# nrf7140_application register map
Vendor: Nordic Semiconductor; Series: nRF71; File version: 1
CPU: CM33 r0p4, little endian, MPU, FPU, 3 interrupt priority bits, 480 interrupts, 8 SAU regions
Registers are 32-bit, read-write, reset 0x0 unless marked. A register's access mark holds for its fields unless they carry their own. Offsets are from the block's base; [hi:lo] are bit positions; lines under a group give offsets from that group; {n}, {i} and the like mark numbered series; 'fields as' and 'values as' point back to an identical list.

## GLOBAL_DISPC_NS (part 2 of 3) — DISPC
Base 0x49004000
0x1000 CORE group — Unspecified
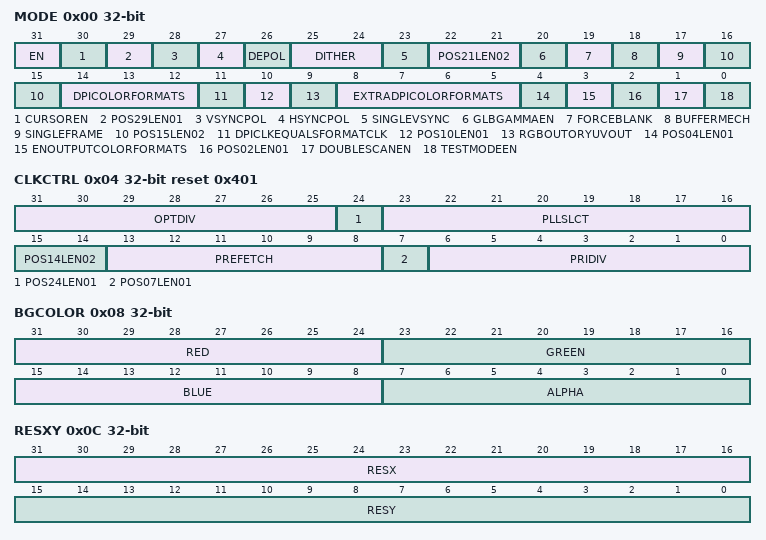
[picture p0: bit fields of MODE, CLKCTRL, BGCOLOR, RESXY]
  0x00 MODE — General control register that activates the NemaDC
    [31] EN — When set to 1, the NemaDC controller is activated
    [30] CURSOREN — When set to 1, cursor is enabled
    [29] POS29LEN01
    [28] VSYNCPOL — Defines VSYNC polarity
    [27] HSYNCPOL — Defines HSYNC polarity
    [26] DEPOL — Defines DE polarity
    [25:24] DITHER — Defines the dithering mode
    [23] SINGLEVSYNC — When set to 1, VSYNC for a single cycle per line is enabled
    [22:21] POS21LEN02
    [20] GLBGAMMAEN — When set to 1, global gamma correction is enabled
    [19] FORCEBLANK — When set to 1, forces output to blank
    [18] BUFFERMECH — When set to 1, a buffer mechanism is enable that waits for the internal
    [17] SINGLEFRAME — When set to 1, single frame update is enabled
    [16:15] POS15LEN02
    [14:12] DPICOLORFORMATS — DPI output color formats
    [11] DPICLKEQUALSFORMATCLK — When set to 1, DPI_PCLK is equal to format_clk
    [10] POS10LEN01
    [9] RGBOUTORYUVOUT — * 1: YUV/YCbCr format is enabled
    [8:5] EXTRADPICOLORFORMATS — Display data format
    [4] POS04LEN01
    [3] ENOUTPUTCOLORFORMATS — When set to 0, the following output color formats are enabled
    [2] POS02LEN01
    [1] DOUBLESCANEN — When set to 1, double horizontal scan is enabled
    [0] TESTMODEEN — When set to 1, test mode is enabled
  0x04 CLKCTRL reset 0x401 — Setup proper timing with divider control bits
    [31:25] OPTDIV — Value of predivider
    [24] POS24LEN01
    [23:16] PLLSLCT — Select PLL Clock. Drives the pll_sw pins
    [15:14] POS14LEN02
    [13:8] PREFETCH — Number of lines to be prefetched before starting the
    [7] POS07LEN01
    [6:0] PRIDIV — Value of primary clock divider
  0x08 BGCOLOR — Specifies the main background color.
    [31:24] RED — Color red is used as background color
    [23:16] GREEN — Color green is used as background color
    [15:8] BLUE — Color blue is used as background color
    [7:0] ALPHA — Color alpha is used as background color
  0x0C RESXY — Specifies the main X and Y resolutions.
    [31:16] RESX — Value of X resolution in pixels
    [15:0] RESY — Value of Y resolution in pixels
  0x10 PLAY — Write any value to this register at the end of the programming sequence to trigger the NemaDC.
    [31:0] PLAY — Trigger the frame generation process
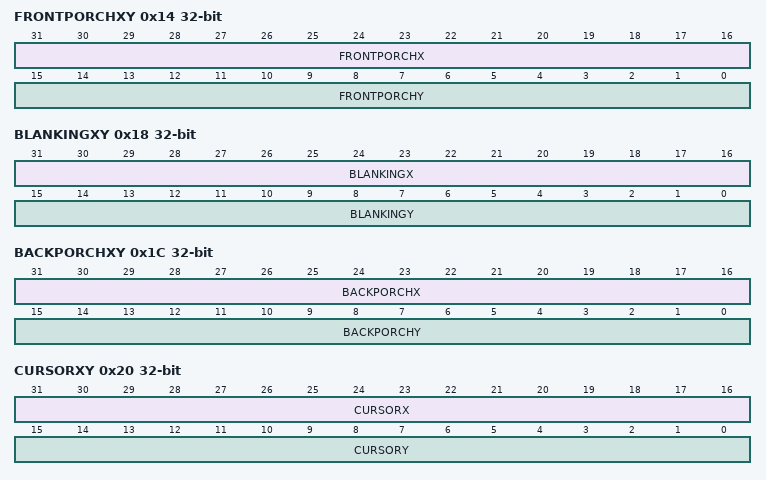
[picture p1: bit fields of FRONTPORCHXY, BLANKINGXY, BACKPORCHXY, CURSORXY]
  0x14 FRONTPORCHXY — Specifies the X and Y dimensions for the Front Porch.
    [31:16] FRONTPORCHX — Specify the pixel clock cycles for the front porch X dimension
    [15:0] FRONTPORCHY — Specify the number of lines for the front porch Y dimension
  0x18 BLANKINGXY — Specifies the X and Y dimensions for the Blanking Period.
    [31:16] BLANKINGX — Specify the HSYNC pulse length for the X dimension blanking period
    [15:0] BLANKINGY — Specify the VSYNC lines for the Y dimension blanking period
  0x1C BACKPORCHXY — Specifies the X and Y dimensions for the Back Porch.
    [31:16] BACKPORCHX — Specify the pixel clock cycles for the back porch X dimension
    [15:0] BACKPORCHY — Specify the number of lines for the front porch Y dimension
  0x20 CURSORXY — Specifies the cursor's start X and Y coordinates.
    [31:16] CURSORX — Specify cursor's X dimension
    [15:0] CURSORY — Specify cursor's Y dimension
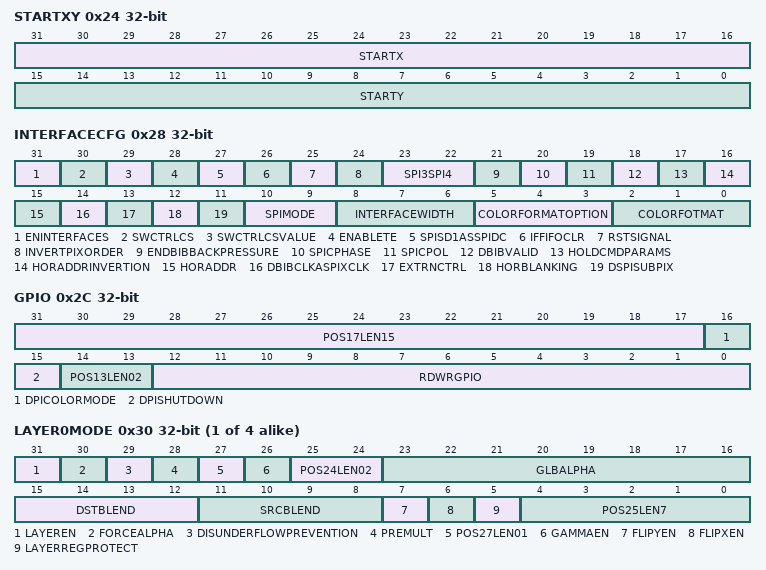
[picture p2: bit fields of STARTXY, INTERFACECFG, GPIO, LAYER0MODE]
  0x24 STARTXY — Specifies the start position of the very first frame.
    [31:16] STARTX — Specify frames's X dimension
    [15:0] STARTY — Specify frames's Y dimension
  0x28 INTERFACECFG — Register for the configuration DBI Type-B interface
    [31] ENINTERFACES — When set to 1, the DBI Type-B/SPI interfaces are activated
    [30] SWCTRLCS — When set to 1, the value of the CSX signal of the DBI Type-B/SPI interfaces
    [29] SWCTRLCSVALUE — Sets the value of DBIB_CSX or SPI_CS signal:
    [28] ENABLETE — When set to 1, the INTERFACE_TE signal is enabled
    [27] SPISD1ASSPIDC — When set to 1, enables the usage of SPI_DC wire as SPI_SD1
    [26] IFFIFOCLR — When set to 1, it clears the data FIFO and the command FIFO
    [25] RSTSIGNAL — Drives DBIB_RESX output signal of DBI Type-B interface
    [24] INVERTPIXORDER — Invert Pixel Order
    [23:22] SPI3SPI4 — Set the SPI 3-wire or 4-wire mode:
    [21] ENDBIBBACKPRESSURE — When set to 1, enables back-pressure for DBI Type-B
    [20] SPICPHASE — Sets SPI Clock Phase
    [19] SPICPOL — Sets SPI Clock Polarity
    [18] DBIBVALID — When set to 1 and a DBIB read operation is performed then it is necessary
    [17] HOLDCMDPARAMS — When set to 1, it holds the commands/parameters and transmit them
    [16] HORADDRINVERTION — When set to 1, inverts the bit-order of the horizontal line address
    [15] HORADDR — When set to 1, two-byte address is sent with each horizontal line (SPI)
    [14] DBIBCLKASPIXCLK — When set to 1, expose pixel generation pipeline clock (pixel_clk) on the DBIB_CLK
    [13] EXTRNCTRL — When set to 1, enables the external control.
    [12] HORBLANKING — When set to 1, enables the horizontal blanking
    [11] DSPISUBPIX — When set to 1, Enables DualSPI sub-pixel transaction
    [10:9] SPIMODE — Set mode of operation SPI/DualSPI/QuadSPI/QuadSPI DDR
    [8:6] INTERFACEWIDTH — Set DBI Type-B interface width (8, 9 or 16 bits) and
    [5:3] COLORFORMATOPTION — Set the data order of the 8-bit data word:
    [2:0] COLORFOTMAT — Set the color format for DBI Type-B/SPI interfaces:
  0x2C GPIO — General Purpose register.
    [31:17] POS17LEN15
    [16] DPICOLORMODE wo — Assert DPI-2 Color Mode Signal
    [15] DPISHUTDOWN wo — Assert DPI-2 Shutdown Signal
    [14:13] POS13LEN02
    [12:0] RDWRGPIO — Read/Write from/to GPIO pins
  {0x30+0x20*j} LAYER{j}MODE (j=0..3) — Activate and set-up layer {j}
    [31] LAYEREN — When set to 1, layer n is enabled
    [30] FORCEALPHA — When set to 1, force alpha with global alpha
    [29] DISUNDERFLOWPREVENTION — When set to 1, it disables the mechanism that prevent the underflow
    [28] PREMULT — When set to 1, premultiply image alpha is enabled
    [27] POS27LEN01
    [26] GAMMAEN — When set to 1, Gamma Look Up Table is enabled
    [25:24] POS24LEN02
    [23:16] GLBALPHA — Alpha layer global value (0x00-0xFF range)
    [15:12] DSTBLEND — Destination blending function for layer {j}.
    [11:8] SRCBLEND — Source blending function for layer {j}.
    [7] FLIPYEN — Enables the FlipY functionality
    [6] FLIPXEN — Enables the FlipX functionality.
    [5] LAYERREGPROTECT — Enable Register Protection for NemaDC layer registers.
    [4:0] POS25LEN7
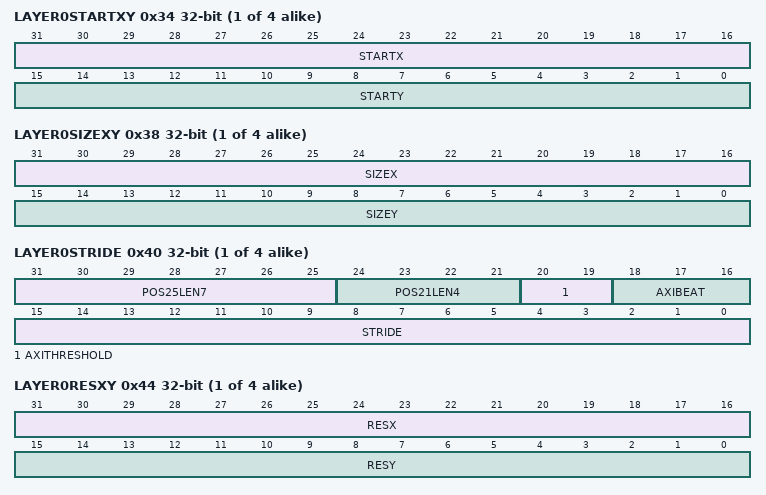
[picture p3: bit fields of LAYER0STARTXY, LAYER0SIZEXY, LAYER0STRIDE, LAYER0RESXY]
  {0x34+0x20*j} LAYER{j}STARTXY (j=0..3) — X and Y start dimensions of layer {j}
    [31:16] STARTX — Specify the pixel offset of the starting X dimension of layer {j}
    [15:0] STARTY — Specify the pixel offset of the starting Y dimension of layer {j}
  {0x38+0x20*j} LAYER{j}SIZEXY (j=0..3) — X and Y size of layer {j}
    [31:16] SIZEX — Specify the pixel size of the layer {j} in the X dimension
    [15:0] SIZEY — Specify the pixel size of the layer {j} in the Y dimension
  {0x3C+0x20*j} LAYER{j}BASEADDR (j=0..3) — The start address of the framebuffer to be accessed by layer {j}
    [31:0] BASEADDR — Specify the start address of framebuffer for layer {j}.
  {0x40+0x20*j} LAYER{j}STRIDE (j=0..3) — Specify the stride and the AXI bus burst of layer {j}
    [31:25] POS25LEN7
    [24:21] POS21LEN4
    [20:19] AXITHRESHOLD — Specify the AXI fifo threshold burst start in layer {j}
    [18:16] AXIBEAT — Specify the AXI-beats per burst in layer {j}
    [15:0] STRIDE — Specify the stride, which is the distance from line to line in bytes for layer {j} memory
  {0x44+0x20*j} LAYER{j}RESXY (j=0..3) — X and Y start dimensions of layerX and Y dimensions for the resolution of layer {j}.
    [31:16] RESX — Specify the layer {j} pixel resolution in the X dimension
    [15:0] RESY — Specify the layer {j} pixel resolution in the Y dimension
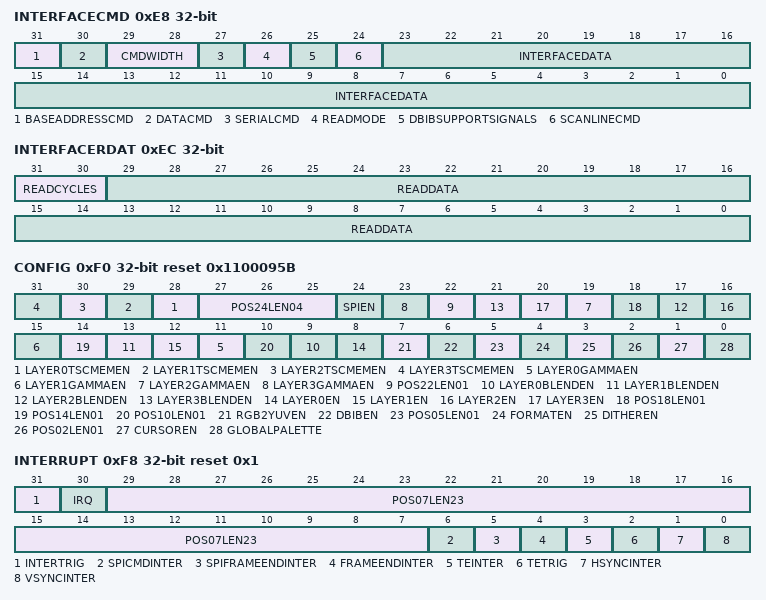
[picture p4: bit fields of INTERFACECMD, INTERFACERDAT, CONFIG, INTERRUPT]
  0xE8 INTERFACECMD — Command Register to read/write commands from/to DBI Type-B/SPI interfaces.
    [31] BASEADDRESSCMD — When set to 0, indicates that the command data are
    [30] DATACMD — Send direct data of type 'command' to the DBI Type-B/SPI interfaces
    [29:28] CMDWIDTH — Determine the command width.
    [27] SERIALCMD — When sets to 1, switch to serial transmission of the
    [26] READMODE — When sets to 1, read mode is enabled
    [25] DBIBSUPPORTSIGNALS — When sets to 1, NEMADC_REG_FORMAT_CTRL[15:8] is exposed on DBIB_CT pins and
    [24] SCANLINECMD — When sets to 1, store internally a command type which is
    [23:0] INTERFACEDATA — Data to send to the DBI Type-B/SPI interfaces
  0xEC INTERFACERDAT — Data read by DBI Type-B/SPI interfaces are stored in the NEMADC_REG_INTERFACE_RDAT register.
    [31:30] READCYCLES — On Write: Specify the number of read cycles for SPI
    [29:0] READDATA ro — Read data from DBI Type-B/SPI interfaces (low bits)
  0xF0 CONFIG reset 0x1100095B — Information register of the layers activation and setup.
    [n+28] LAYER{n}TSCMEMEN ro (n=0..3) — Indicates that layer {n} has TSC Memory
    [27:25] POS24LEN04 ro
    [24] SPIEN ro — Indicates that SPI interface is enabled
    [4n+11] LAYER{n}GAMMAEN ro (n=0..3) — Indicates that layer {n} has gamma LUT
    [22] POS22LEN01 ro
    [4n+9] LAYER{n}BLENDEN ro (n=0..3) — Indicates that layer {n} has blender
    [4n+8] LAYER{n}EN ro (n=0..3) — Indicates that layer {n} is enabled
    [18] POS18LEN01 ro
    [14] POS14LEN01 ro
    [10] POS10LEN01 ro
    [7] RGB2YUVEN ro — Indicates that RGB to YUV/YCbCr converter is enabled
    [6] DBIBEN ro — Indicates that DBI Type-B interface is enabled
    [5] POS05LEN01 ro
    [4] FORMATEN ro — Indicates that formatting is enabled
    [3] DITHEREN ro — Indicates that dithering is enabled
    [2] POS02LEN01 ro
    [1] CURSOREN ro — Indicates that cursor is enabled
    [0] GLOBALPALETTE ro — Indicates that Global Gamma/Palette is enabled
  0xF4 IDREG reset 0x87452365 — Identification Register.
    [31:0] IDREG ro — Constant ID value
  0xF8 INTERRUPT reset 0x1
    [31] INTERTRIG — Interrupt request trigger control
    [30] IRQ ro — Indicates IRQ is underway
    [29:7] POS07LEN23
    [6] SPICMDINTER — When set to 1, signals an interrupt when SPI interfaces
    [5] SPIFRAMEENDINTER — When set to 1, signals an interrupt when SPI interfaces
    [4] FRAMEENDINTER — When set to 1, signals an interrupt on Frame End
    [3] TEINTER — When set to 1, TE interrupt enabled
    [2] TETRIG — TE interrupt trigger control
    [1] HSYNCINTER — When set to 1, HSYNC interrupt enabled
    [0] VSYNCINTER — When set to 1, VSYNC interrupt enabled
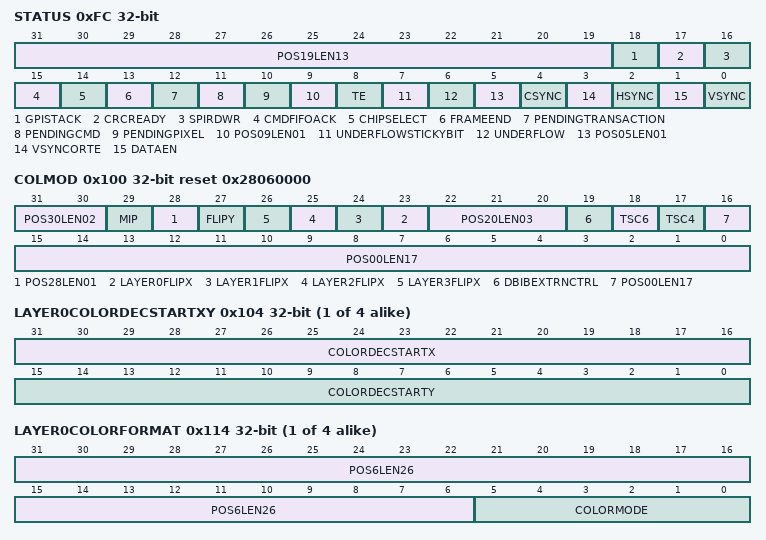
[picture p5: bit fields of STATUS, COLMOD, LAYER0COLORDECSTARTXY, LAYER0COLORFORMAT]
  0xFC STATUS — On read, returns NemaDC's status.
    [31:19] POS19LEN13 ro
    [18] GPISTACK ro — Indicates GPI got stack durring packet transaction
    [17] CRCREADY ro — Indicates CRC Register read ready
    [16] SPIRDWR ro — Indicates read/write operation on SPI
    [15] CMDFIFOACK ro — Indicates the DBI/SPI Command fifo ack
    [14] CHIPSELECT ro — Indicates DBI/SPI CS status
    [13] FRAMEEND ro — Indicates Frame end
    [12] PENDINGTRANSACTION ro — Indicates pending output transaction in DBI Type-B/SPI interfaces
    [11] PENDINGCMD ro — Indicates pending commands in DBI Type-B/SPI interfaces
    [10] PENDINGPIXEL ro — Indicates pending RGB data in DBI Type-B/SPI interfaces
    [9] POS09LEN01 ro
    [8] TE ro — Indicates DBI Type-B/SPI tearing effect
    [7] UNDERFLOWSTICKYBIT ro — Indicates sticky underflow. This bit clears when status register is written
    [6] UNDERFLOW ro — Indicates current underflow
    [5] POS05LEN01 ro
    [4] CSYNC ro — Indicates the CSYNC signal status (0 or 1) at the current time of reading
    [3] VSYNCORTE ro — Indicates the VSYNC signal status and the tearing effect signal
    [2] HSYNC ro — Indicates the HSYNC signal status (0 or 1) at the current time of reading
    [1] DATAEN ro — Indicates the DE signal status (0 or 1) at the current time of reading
    [0] VSYNC ro — Indicates that the controller is not in active vertical blanking
  0x100 COLMOD reset 0x28060000 — Color mode status register.
    [31:30] POS30LEN02 ro
    [29] MIP ro — High value indicate that NemaDC is equiped with MiP-Parallel interface
    [28] POS28LEN01 ro
    [27] FLIPY ro — High value indicate that FlipY is equiped
    [n+23] LAYER{n}FLIPX ro (n=0..3) — High value indicate that FlipX is equiped for Layer {n}
    [22:20] POS20LEN03 ro
    [19] DBIBEXTRNCTRL ro — High value indicate that DBIB external control is enabled
    [18] TSC6 ro — High value indicate that TSC6 is enabled
    [17] TSC4 ro — High value indicates that TSC4 is enabled
    [16:0] POS00LEN17 ro
  {0x104+4j} LAYER{j}COLORDECSTARTXY (j=0..3) — X and Y start dimensions of colordec in layer {j}
    [31:16] COLORDECSTARTX — Specify the pixel offset of the starting X dimension of colordec in layer {j}.
    [15:0] COLORDECSTARTY — Specify the pixel offset of the starting Y dimension of colordec in layer {j}.
  {0x114+4j} LAYER{j}COLORFORMAT (j=0..3) — Specify the color format of layer {j}
    [31:6] POS6LEN26
    [5:0] COLORMODE — Color mode for layer {j}.
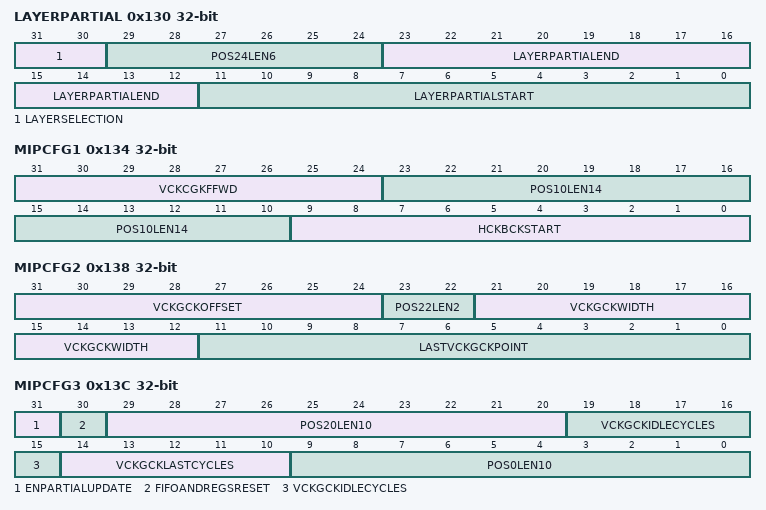
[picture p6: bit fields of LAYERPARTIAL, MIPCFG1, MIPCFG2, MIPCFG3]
  0x130 LAYERPARTIAL — MiP partial and full frame update register, used by layers.
    [31:30] LAYERSELECTION — Indicates the layer that the partial or full frame region belongs to.
    [29:24] POS24LEN6
    [23:12] LAYERPARTIALEND — Indicates the last visible row of the layer for the given partial or full frame region.
    [11:0] LAYERPARTIALSTART — Indicates the first visible row of the layer for the given partial or full frame region.
  0x134 MIPCFG1 — MiP partial and full frame update configuration register, used by MiP-Parallel interface.
    [31:24] VCKCGKFFWD — Indicates the VCK/GCK (high/low) width of a fast forward transaction
    [23:10] POS10LEN14
    [9:0] HCKBCKSTART — Indicates the HCK/BCK count that the MiP-Parallel interface
  0x138 MIPCFG2 — MiP partial and full frame update configuration register, used by MiP-Parallel interface.
    [31:24] VCKGCKOFFSET — Indicates the VCK/GCK offset.
    [23:22] POS22LEN2
    [21:12] VCKGCKWIDTH — Indicates the VCK/GCK (high/low) width during a normal transaction.
    [11:0] LASTVCKGCKPOINT — Indicates the last VCK/GCK count with valid data.
  0x13C MIPCFG3 — MiP partial and full frame update configuration register, used by MiP-Parallel interface.
    [31] ENPARTIALUPDATE — Enables partial update in MiP-Parallel interface.
    [30] FIFOANDREGSRESET — When set to 1, it resets all the MiP-Parallel interface fifos and registers. Layers must be active.
    [29:20] POS20LEN10
    [19:15] VCKGCKIDLECYCLES — Indicates the VCK/GCK idle counts before the transmission of valid data.
    [14:10] VCKGCKLASTCYCLES — Indicates the number of the last VCK/GCK counts that are transmitted
    [9:0] POS0LEN10
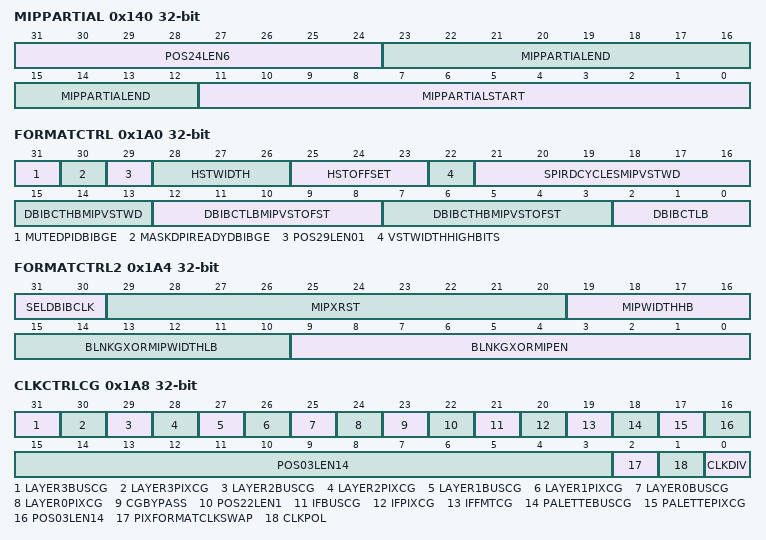
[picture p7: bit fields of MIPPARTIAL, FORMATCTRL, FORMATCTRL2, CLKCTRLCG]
  0x140 MIPPARTIAL — MiP partial and full frame update register, used by MiP-Parallel interface.
    [31:24] POS24LEN6
    [23:12] MIPPARTIALEND — Indicates the last row of the given partial or full frame region.
    [11:0] MIPPARTIALSTART — Indicates the first row of the given partial or full frame region.
  0x180 IPVERSION reset 0x230601 — Indicates the current version of NemaDC IP
    [31:0] TLCDVERSION ro — The current version of NemaDC IP
  0x184 CRC — If CRC errors occur, they are written in the NEMADC_REG_CRC register
    [31:0] CRC ro — CRC value if CRC error exists
  0x1A0 FORMATCTRL — Controls SPI, DBI and MiP-Parallel format.
    [31] MUTEDPIDBIBGE — When DBI-Type B Interface is selected
    [30] MASKDPIREADYDBIBGE — When DBI-Type B Interface is selected
    [29] POS29LEN01
    [28:26] HSTWIDTH — When DBI-Type B or SPI Interfaces is selected
    [25:23] HSTOFFSET — When DBI-Type B or SPI Interfaces is selected
    [22] VSTWIDTHHIGHBITS — When DBI-Type B or SPI Interfaces is selected
    [21:16] SPIRDCYCLESMIPVSTWD — When SPI Interface is selected
    [15:13] DBIBCTHBMIPVSTWD — When DBI-Type B Interface is selected
    [12:8] DBIBCTLBMIPVSTOFST — When DBI-Type B Interface is selected
    [7:3] DBIBCTHBMIPVSTOFST — When DBI-Type B Interface is selected
    [2:0] DBIBCTLB — When DBI-Type B Interface is selected
  0x1A4 FORMATCTRL2 — Controls DBI, SPI and MiP-Parallel format.
    [31:30] SELDBIBCLK — Set the exposition of DBIB_CLK based on the following options:
    [29:20] MIPXRST — When DBI-Type B or SPI Interface is selected
    [19:16] MIPWIDTHHB — When DBI-Type B or SPI Interface is selected
    [15:10] BLNKGXORMIPWIDTHLB — When DBI-Type B or SPI Interface is selected
    [9:0] BLNKGXORMIPEN — When DBI-Type B or SPI Interface is selected
  0x1A8 CLKCTRLCG — Controls the Clock Gaters and the routing of format and pixel clock
    [31] LAYER3BUSCG wo — layer 3 bus clock clock-gater bypass
    [30] LAYER3PIXCG wo — layer 3 pixel clock clock-gater bypass
    [29] LAYER2BUSCG wo — layer 2 bus clock clock-gater bypass
    [28] LAYER2PIXCG wo — layer 2 pixel clock clock-gater bypass
    [27] LAYER1BUSCG wo — layer 1 bus clock clock-gater bypass
    [26] LAYER1PIXCG wo — layer 1 pixel clock clock-gater bypass
    [25] LAYER0BUSCG — layer 0 bus clock clock-gater bypass
    [24] LAYER0PIXCG — layer 0 pixel clock clock-gater bypass
    [23] CGBYPASS — RegFile clock-gaters bypass
    [22] POS22LEN1
    [21] IFBUSCG — Interfaces bus clock clock-gater bypass
    [20] IFPIXCG — Interfaces pixel clock clock-gater bypass
    [19] IFFMTCG — Interfaces format clock clock-gater bypass
    [18] PALETTEBUSCG — Palette bus clock clock-gater bypass
    [17] PALETTEPIXCG — Palette pixel clock clock-gater bypass
    [16:3] POS03LEN14
    [2] PIXFORMATCLKSWAP — Pixel generation and format clock swap
    [1] CLKPOL — Invert (ouput) clock polarity
    [0] CLKDIV — Enable clock divider
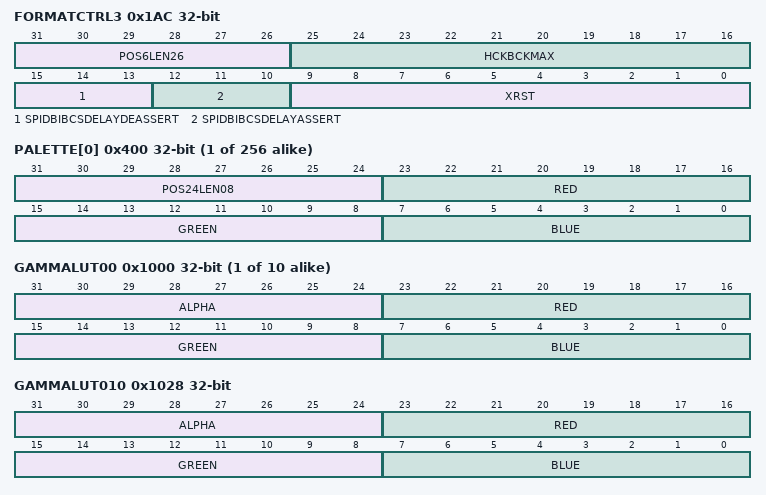
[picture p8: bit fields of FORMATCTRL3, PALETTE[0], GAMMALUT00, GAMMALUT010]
  0x1AC FORMATCTRL3 — Control MiP-Parallel format.
    [31:26] POS6LEN26
    [25:16] HCKBCKMAX — Inidates the maximum value of HCK/BCK count for MiP-Parallel interface.
    [15:13] SPIDBIBCSDELAYDEASSERT — For SPI:
    [12:10] SPIDBIBCSDELAYASSERT — For SPI:
    [9:0] XRST — Set the high state of XRST signal in multiple of VCK
  {0x400+4j} PALETTE[{j}] (j=0..255) — Description collection: Global palette/gamma correction memory region.
    [31:24] POS24LEN08 wo
    [23:16] RED wo — Gamma ramp red bits.
    [15:8] GREEN wo — Gamma ramp green bits.
    [7:0] BLUE wo — Gamma ramp blue bits.
  {0x1000+4j} GAMMALUT{j:02} (j=0..9) — Layer 0 palette/gamma correction memory region.
    [31:24] ALPHA wo — Color alpha is used as Lut color.
    [23:16] RED wo — Color red is used as Lut color.
    [15:8] GREEN wo — Color green is used as Lut color.
    [7:0] BLUE wo — Color blue is used as Lut color.
  0x1028 GAMMALUT010 — Layer 0 palette/gamma correction memory region.
    fields as CORE.GAMMALUT00
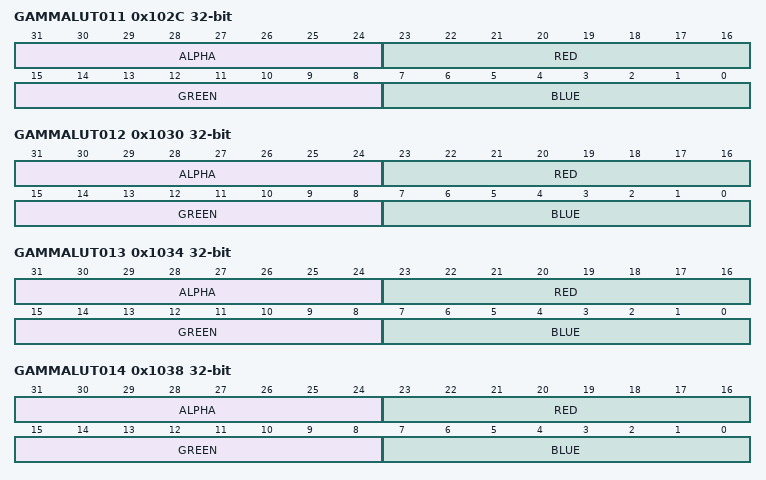
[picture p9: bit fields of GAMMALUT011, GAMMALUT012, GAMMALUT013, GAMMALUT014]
  0x102C GAMMALUT011 — Layer 0 palette/gamma correction memory region.
    fields as CORE.GAMMALUT00
  0x1030 GAMMALUT012 — Layer 0 palette/gamma correction memory region.
    fields as CORE.GAMMALUT00
  0x1034 GAMMALUT013 — Layer 0 palette/gamma correction memory region.
    fields as CORE.GAMMALUT00
  0x1038 GAMMALUT014 — Layer 0 palette/gamma correction memory region.
    fields as CORE.GAMMALUT00
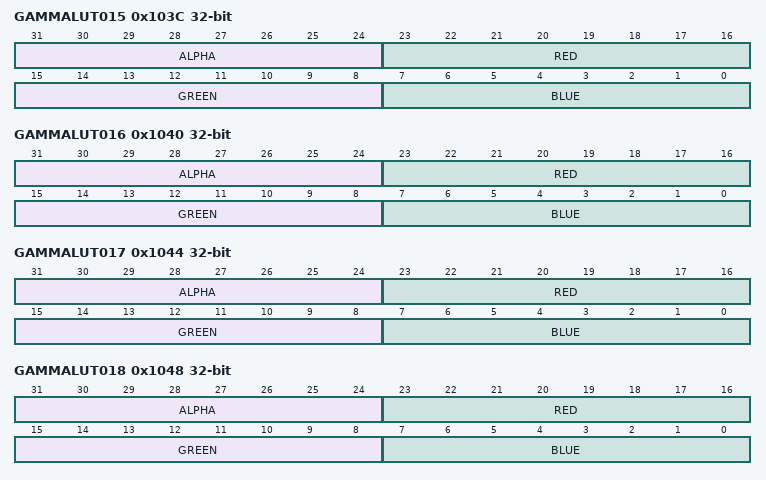
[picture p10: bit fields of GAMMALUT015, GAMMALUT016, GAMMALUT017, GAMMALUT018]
  0x103C GAMMALUT015 — Layer 0 palette/gamma correction memory region.
    fields as CORE.GAMMALUT00
  0x1040 GAMMALUT016 — Layer 0 palette/gamma correction memory region.
    fields as CORE.GAMMALUT00
  0x1044 GAMMALUT017 — Layer 0 palette/gamma correction memory region.
    fields as CORE.GAMMALUT00
  0x1048 GAMMALUT018 — Layer 0 palette/gamma correction memory region.
    fields as CORE.GAMMALUT00
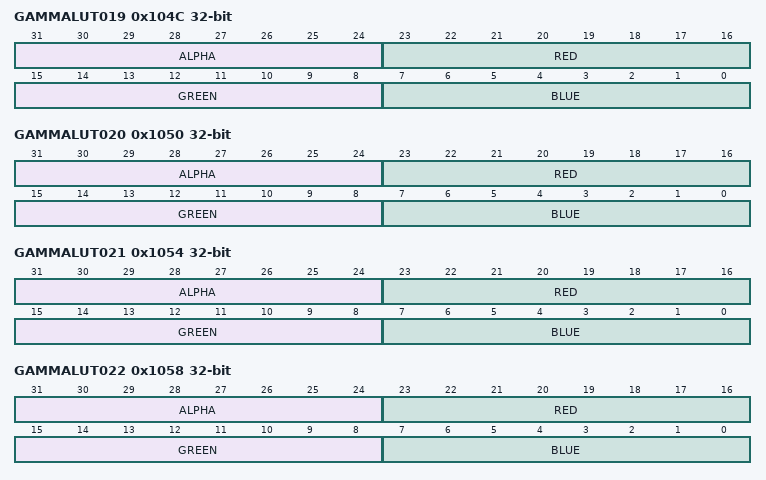
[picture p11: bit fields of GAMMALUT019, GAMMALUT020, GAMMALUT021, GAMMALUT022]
  0x104C GAMMALUT019 — Layer 0 palette/gamma correction memory region.
    fields as CORE.GAMMALUT00
  0x1050 GAMMALUT020 — Layer 0 palette/gamma correction memory region.
    fields as CORE.GAMMALUT00
  0x1054 GAMMALUT021 — Layer 0 palette/gamma correction memory region.
    fields as CORE.GAMMALUT00
  0x1058 GAMMALUT022 — Layer 0 palette/gamma correction memory region.
    fields as CORE.GAMMALUT00
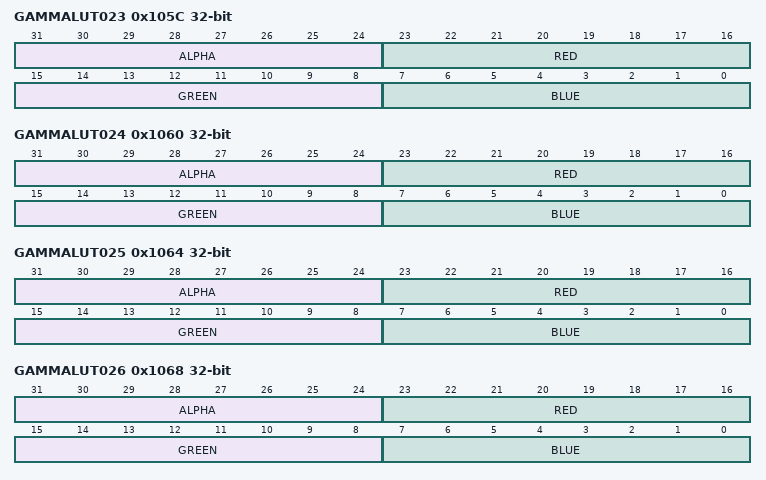
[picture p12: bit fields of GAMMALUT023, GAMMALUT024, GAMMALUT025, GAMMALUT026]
  0x105C GAMMALUT023 — Layer 0 palette/gamma correction memory region.
    fields as CORE.GAMMALUT00
  0x1060 GAMMALUT024 — Layer 0 palette/gamma correction memory region.
    fields as CORE.GAMMALUT00
  0x1064 GAMMALUT025 — Layer 0 palette/gamma correction memory region.
    fields as CORE.GAMMALUT00
  0x1068 GAMMALUT026 — Layer 0 palette/gamma correction memory region.
    fields as CORE.GAMMALUT00
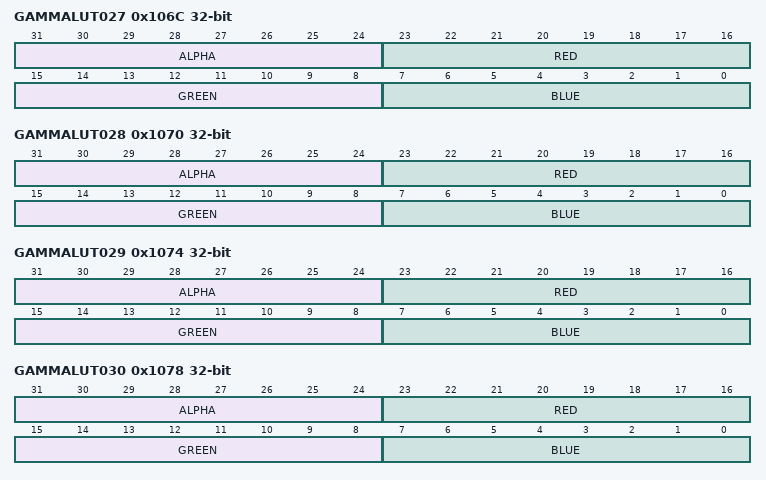
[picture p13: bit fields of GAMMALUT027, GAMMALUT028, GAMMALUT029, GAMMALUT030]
  0x106C GAMMALUT027 — Layer 0 palette/gamma correction memory region.
    fields as CORE.GAMMALUT00
  0x1070 GAMMALUT028 — Layer 0 palette/gamma correction memory region.
    fields as CORE.GAMMALUT00
  0x1074 GAMMALUT029 — Layer 0 palette/gamma correction memory region.
    fields as CORE.GAMMALUT00
  0x1078 GAMMALUT030 — Layer 0 palette/gamma correction memory region.
    fields as CORE.GAMMALUT00
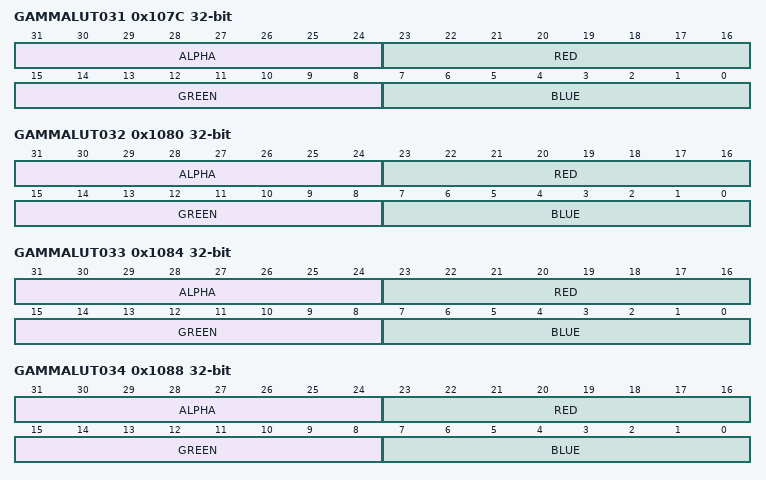
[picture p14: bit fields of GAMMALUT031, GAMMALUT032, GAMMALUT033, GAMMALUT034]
  0x107C GAMMALUT031 — Layer 0 palette/gamma correction memory region.
    fields as CORE.GAMMALUT00
  0x1080 GAMMALUT032 — Layer 0 palette/gamma correction memory region.
    fields as CORE.GAMMALUT00
  0x1084 GAMMALUT033 — Layer 0 palette/gamma correction memory region.
    fields as CORE.GAMMALUT00
  0x1088 GAMMALUT034 — Layer 0 palette/gamma correction memory region.
    fields as CORE.GAMMALUT00
  0x108C GAMMALUT035 — Layer 0 palette/gamma correction memory region.
    fields as CORE.GAMMALUT00
  0x1090 GAMMALUT036 — Layer 0 palette/gamma correction memory region.
    fields as CORE.GAMMALUT00
  0x1094 GAMMALUT037 — Layer 0 palette/gamma correction memory region.
    fields as CORE.GAMMALUT00
  0x1098 GAMMALUT038 — Layer 0 palette/gamma correction memory region.
    fields as CORE.GAMMALUT00
  0x109C GAMMALUT039 — Layer 0 palette/gamma correction memory region.
    fields as CORE.GAMMALUT00
  {0x1000+4j} GAMMALUT{j:03} (j=40..99) — Layer 0 palette/gamma correction memory region.
    fields as CORE.GAMMALUT00
  {0x1000+4j} GAMMALUT{j:04} (j=100..110) — Layer 0 palette/gamma correction memory region.
    fields as CORE.GAMMALUT00
  0x11BC GAMMALUT0111 — Layer 0 palette/gamma correction memory region.
    fields as CORE.GAMMALUT00
  0x11C0 GAMMALUT0112 — Layer 0 palette/gamma correction memory region.
    fields as CORE.GAMMALUT00
  0x11C4 GAMMALUT0113 — Layer 0 palette/gamma correction memory region.
    fields as CORE.GAMMALUT00
  0x11C8 GAMMALUT0114 — Layer 0 palette/gamma correction memory region.
    fields as CORE.GAMMALUT00
  0x11CC GAMMALUT0115 — Layer 0 palette/gamma correction memory region.
    fields as CORE.GAMMALUT00
  0x11D0 GAMMALUT0116 — Layer 0 palette/gamma correction memory region.
    fields as CORE.GAMMALUT00
  0x11D4 GAMMALUT0117 — Layer 0 palette/gamma correction memory region.
    fields as CORE.GAMMALUT00
  0x11D8 GAMMALUT0118 — Layer 0 palette/gamma correction memory region.
    fields as CORE.GAMMALUT00
  0x11DC GAMMALUT0119 — Layer 0 palette/gamma correction memory region.
    fields as CORE.GAMMALUT00
  0x11E0 GAMMALUT0120 — Layer 0 palette/gamma correction memory region.
    fields as CORE.GAMMALUT00
  0x11E4 GAMMALUT0121 — Layer 0 palette/gamma correction memory region.
    fields as CORE.GAMMALUT00
  0x11E8 GAMMALUT0122 — Layer 0 palette/gamma correction memory region.
    fields as CORE.GAMMALUT00
  0x11EC GAMMALUT0123 — Layer 0 palette/gamma correction memory region.
    fields as CORE.GAMMALUT00
  0x11F0 GAMMALUT0124 — Layer 0 palette/gamma correction memory region.
    fields as CORE.GAMMALUT00
  0x11F4 GAMMALUT0125 — Layer 0 palette/gamma correction memory region.
    fields as CORE.GAMMALUT00
  0x11F8 GAMMALUT0126 — Layer 0 palette/gamma correction memory region.
    fields as CORE.GAMMALUT00
  0x11FC GAMMALUT0127 — Layer 0 palette/gamma correction memory region.
    fields as CORE.GAMMALUT00
  0x1200 GAMMALUT0128 — Layer 0 palette/gamma correction memory region.
    fields as CORE.GAMMALUT00
  0x1204 GAMMALUT0129 — Layer 0 palette/gamma correction memory region.
    fields as CORE.GAMMALUT00
  0x1208 GAMMALUT0130 — Layer 0 palette/gamma correction memory region.
    fields as CORE.GAMMALUT00
  0x120C GAMMALUT0131 — Layer 0 palette/gamma correction memory region.
    fields as CORE.GAMMALUT00
  0x1210 GAMMALUT0132 — Layer 0 palette/gamma correction memory region.
    fields as CORE.GAMMALUT00
  0x1214 GAMMALUT0133 — Layer 0 palette/gamma correction memory region.
    fields as CORE.GAMMALUT00
  0x1218 GAMMALUT0134 — Layer 0 palette/gamma correction memory region.
    fields as CORE.GAMMALUT00
  0x121C GAMMALUT0135 — Layer 0 palette/gamma correction memory region.
    fields as CORE.GAMMALUT00
  0x1220 GAMMALUT0136 — Layer 0 palette/gamma correction memory region.
    fields as CORE.GAMMALUT00
  0x1224 GAMMALUT0137 — Layer 0 palette/gamma correction memory region.
    fields as CORE.GAMMALUT00
  0x1228 GAMMALUT0138 — Layer 0 palette/gamma correction memory region.
    fields as CORE.GAMMALUT00
  0x122C GAMMALUT0139 — Layer 0 palette/gamma correction memory region.
    fields as CORE.GAMMALUT00
  0x1230 GAMMALUT0140 — Layer 0 palette/gamma correction memory region.
    fields as CORE.GAMMALUT00
  0x1234 GAMMALUT0141 — Layer 0 palette/gamma correction memory region.
    fields as CORE.GAMMALUT00
  0x1238 GAMMALUT0142 — Layer 0 palette/gamma correction memory region.
    fields as CORE.GAMMALUT00
  0x123C GAMMALUT0143 — Layer 0 palette/gamma correction memory region.
    fields as CORE.GAMMALUT00
  0x1240 GAMMALUT0144 — Layer 0 palette/gamma correction memory region.
    fields as CORE.GAMMALUT00
  0x1244 GAMMALUT0145 — Layer 0 palette/gamma correction memory region.
    fields as CORE.GAMMALUT00
  0x1248 GAMMALUT0146 — Layer 0 palette/gamma correction memory region.
    fields as CORE.GAMMALUT00
  0x124C GAMMALUT0147 — Layer 0 palette/gamma correction memory region.
    fields as CORE.GAMMALUT00
  0x1250 GAMMALUT0148 — Layer 0 palette/gamma correction memory region.
    fields as CORE.GAMMALUT00
  0x1254 GAMMALUT0149 — Layer 0 palette/gamma correction memory region.
    fields as CORE.GAMMALUT00
  0x1258 GAMMALUT0150 — Layer 0 palette/gamma correction memory region.
    fields as CORE.GAMMALUT00
  0x125C GAMMALUT0151 — Layer 0 palette/gamma correction memory region.
    fields as CORE.GAMMALUT00
  0x1260 GAMMALUT0152 — Layer 0 palette/gamma correction memory region.
    fields as CORE.GAMMALUT00
  0x1264 GAMMALUT0153 — Layer 0 palette/gamma correction memory region.
    fields as CORE.GAMMALUT00
  0x1268 GAMMALUT0154 — Layer 0 palette/gamma correction memory region.
    fields as CORE.GAMMALUT00
  0x126C GAMMALUT0155 — Layer 0 palette/gamma correction memory region.
    fields as CORE.GAMMALUT00
  0x1270 GAMMALUT0156 — Layer 0 palette/gamma correction memory region.
    fields as CORE.GAMMALUT00
  0x1274 GAMMALUT0157 — Layer 0 palette/gamma correction memory region.
    fields as CORE.GAMMALUT00
  0x1278 GAMMALUT0158 — Layer 0 palette/gamma correction memory region.
    fields as CORE.GAMMALUT00
  0x127C GAMMALUT0159 — Layer 0 palette/gamma correction memory region.
    fields as CORE.GAMMALUT00
  0x1280 GAMMALUT0160 — Layer 0 palette/gamma correction memory region.
    fields as CORE.GAMMALUT00
  0x1284 GAMMALUT0161 — Layer 0 palette/gamma correction memory region.
    fields as CORE.GAMMALUT00
  0x1288 GAMMALUT0162 — Layer 0 palette/gamma correction memory region.
    fields as CORE.GAMMALUT00
  0x128C GAMMALUT0163 — Layer 0 palette/gamma correction memory region.
    fields as CORE.GAMMALUT00
  0x1290 GAMMALUT0164 — Layer 0 palette/gamma correction memory region.
    fields as CORE.GAMMALUT00
  0x1294 GAMMALUT0165 — Layer 0 palette/gamma correction memory region.
    fields as CORE.GAMMALUT00
  0x1298 GAMMALUT0166 — Layer 0 palette/gamma correction memory region.
    fields as CORE.GAMMALUT00
  0x129C GAMMALUT0167 — Layer 0 palette/gamma correction memory region.
    fields as CORE.GAMMALUT00
  0x12A0 GAMMALUT0168 — Layer 0 palette/gamma correction memory region.
    fields as CORE.GAMMALUT00
  0x12A4 GAMMALUT0169 — Layer 0 palette/gamma correction memory region.
    fields as CORE.GAMMALUT00
  0x12A8 GAMMALUT0170 — Layer 0 palette/gamma correction memory region.
    fields as CORE.GAMMALUT00
  0x12AC GAMMALUT0171 — Layer 0 palette/gamma correction memory region.
    fields as CORE.GAMMALUT00
  0x12B0 GAMMALUT0172 — Layer 0 palette/gamma correction memory region.
    fields as CORE.GAMMALUT00
  0x12B4 GAMMALUT0173 — Layer 0 palette/gamma correction memory region.
    fields as CORE.GAMMALUT00
  0x12B8 GAMMALUT0174 — Layer 0 palette/gamma correction memory region.
    fields as CORE.GAMMALUT00
  0x12BC GAMMALUT0175 — Layer 0 palette/gamma correction memory region.
    fields as CORE.GAMMALUT00
  0x12C0 GAMMALUT0176 — Layer 0 palette/gamma correction memory region.
    fields as CORE.GAMMALUT00
  0x12C4 GAMMALUT0177 — Layer 0 palette/gamma correction memory region.
    fields as CORE.GAMMALUT00
  0x12C8 GAMMALUT0178 — Layer 0 palette/gamma correction memory region.
    fields as CORE.GAMMALUT00
  0x12CC GAMMALUT0179 — Layer 0 palette/gamma correction memory region.
    fields as CORE.GAMMALUT00
  0x12D0 GAMMALUT0180 — Layer 0 palette/gamma correction memory region.
    fields as CORE.GAMMALUT00
  0x12D4 GAMMALUT0181 — Layer 0 palette/gamma correction memory region.
    fields as CORE.GAMMALUT00
  0x12D8 GAMMALUT0182 — Layer 0 palette/gamma correction memory region.
    fields as CORE.GAMMALUT00
  0x12DC GAMMALUT0183 — Layer 0 palette/gamma correction memory region.
    fields as CORE.GAMMALUT00
  0x12E0 GAMMALUT0184 — Layer 0 palette/gamma correction memory region.
    fields as CORE.GAMMALUT00
  0x12E4 GAMMALUT0185 — Layer 0 palette/gamma correction memory region.
    fields as CORE.GAMMALUT00
  0x12E8 GAMMALUT0186 — Layer 0 palette/gamma correction memory region.
    fields as CORE.GAMMALUT00
  0x12EC GAMMALUT0187 — Layer 0 palette/gamma correction memory region.
    fields as CORE.GAMMALUT00
  0x12F0 GAMMALUT0188 — Layer 0 palette/gamma correction memory region.
    fields as CORE.GAMMALUT00
  0x12F4 GAMMALUT0189 — Layer 0 palette/gamma correction memory region.
    fields as CORE.GAMMALUT00
  0x12F8 GAMMALUT0190 — Layer 0 palette/gamma correction memory region.
    fields as CORE.GAMMALUT00
  0x12FC GAMMALUT0191 — Layer 0 palette/gamma correction memory region.
    fields as CORE.GAMMALUT00
  0x1300 GAMMALUT0192 — Layer 0 palette/gamma correction memory region.
    fields as CORE.GAMMALUT00
  0x1304 GAMMALUT0193 — Layer 0 palette/gamma correction memory region.
    fields as CORE.GAMMALUT00
  0x1308 GAMMALUT0194 — Layer 0 palette/gamma correction memory region.
    fields as CORE.GAMMALUT00
  0x130C GAMMALUT0195 — Layer 0 palette/gamma correction memory region.
    fields as CORE.GAMMALUT00
  0x1310 GAMMALUT0196 — Layer 0 palette/gamma correction memory region.
    fields as CORE.GAMMALUT00
  0x1314 GAMMALUT0197 — Layer 0 palette/gamma correction memory region.
    fields as CORE.GAMMALUT00
  0x1318 GAMMALUT0198 — Layer 0 palette/gamma correction memory region.
    fields as CORE.GAMMALUT00
  0x131C GAMMALUT0199 — Layer 0 palette/gamma correction memory region.
    fields as CORE.GAMMALUT00
  {0x1000+4j} GAMMALUT{j:04} (j=200..210) — Layer 0 palette/gamma correction memory region.
    fields as CORE.GAMMALUT00
  0x134C GAMMALUT0211 — Layer 0 palette/gamma correction memory region.
    fields as CORE.GAMMALUT00
  0x1350 GAMMALUT0212 — Layer 0 palette/gamma correction memory region.
    fields as CORE.GAMMALUT00
  0x1354 GAMMALUT0213 — Layer 0 palette/gamma correction memory region.
    fields as CORE.GAMMALUT00
  0x1358 GAMMALUT0214 — Layer 0 palette/gamma correction memory region.
    fields as CORE.GAMMALUT00
  0x135C GAMMALUT0215 — Layer 0 palette/gamma correction memory region.
    fields as CORE.GAMMALUT00
  0x1360 GAMMALUT0216 — Layer 0 palette/gamma correction memory region.
    fields as CORE.GAMMALUT00
  0x1364 GAMMALUT0217 — Layer 0 palette/gamma correction memory region.
    fields as CORE.GAMMALUT00
  0x1368 GAMMALUT0218 — Layer 0 palette/gamma correction memory region.
    fields as CORE.GAMMALUT00
  0x136C GAMMALUT0219 — Layer 0 palette/gamma correction memory region.
    fields as CORE.GAMMALUT00
  0x1370 GAMMALUT0220 — Layer 0 palette/gamma correction memory region.
    fields as CORE.GAMMALUT00
  0x1374 GAMMALUT0221 — Layer 0 palette/gamma correction memory region.
    fields as CORE.GAMMALUT00
  0x1378 GAMMALUT0222 — Layer 0 palette/gamma correction memory region.
    fields as CORE.GAMMALUT00
  0x137C GAMMALUT0223 — Layer 0 palette/gamma correction memory region.
    fields as CORE.GAMMALUT00
  0x1380 GAMMALUT0224 — Layer 0 palette/gamma correction memory region.
    fields as CORE.GAMMALUT00
  0x1384 GAMMALUT0225 — Layer 0 palette/gamma correction memory region.
    fields as CORE.GAMMALUT00
  0x1388 GAMMALUT0226 — Layer 0 palette/gamma correction memory region.
    fields as CORE.GAMMALUT00
  0x138C GAMMALUT0227 — Layer 0 palette/gamma correction memory region.
    fields as CORE.GAMMALUT00
  0x1390 GAMMALUT0228 — Layer 0 palette/gamma correction memory region.
    fields as CORE.GAMMALUT00
  0x1394 GAMMALUT0229 — Layer 0 palette/gamma correction memory region.
    fields as CORE.GAMMALUT00
  0x1398 GAMMALUT0230 — Layer 0 palette/gamma correction memory region.
    fields as CORE.GAMMALUT00
  0x139C GAMMALUT0231 — Layer 0 palette/gamma correction memory region.
    fields as CORE.GAMMALUT00
  0x13A0 GAMMALUT0232 — Layer 0 palette/gamma correction memory region.
    fields as CORE.GAMMALUT00
  0x13A4 GAMMALUT0233 — Layer 0 palette/gamma correction memory region.
    fields as CORE.GAMMALUT00
  0x13A8 GAMMALUT0234 — Layer 0 palette/gamma correction memory region.
    fields as CORE.GAMMALUT00
  0x13AC GAMMALUT0235 — Layer 0 palette/gamma correction memory region.
    fields as CORE.GAMMALUT00
  0x13B0 GAMMALUT0236 — Layer 0 palette/gamma correction memory region.
    fields as CORE.GAMMALUT00
  0x13B4 GAMMALUT0237 — Layer 0 palette/gamma correction memory region.
    fields as CORE.GAMMALUT00
  0x13B8 GAMMALUT0238 — Layer 0 palette/gamma correction memory region.
    fields as CORE.GAMMALUT00
  0x13BC GAMMALUT0239 — Layer 0 palette/gamma correction memory region.
    fields as CORE.GAMMALUT00
  0x13C0 GAMMALUT0240 — Layer 0 palette/gamma correction memory region.
    fields as CORE.GAMMALUT00
  0x13C4 GAMMALUT0241 — Layer 0 palette/gamma correction memory region.
    fields as CORE.GAMMALUT00
  0x13C8 GAMMALUT0242 — Layer 0 palette/gamma correction memory region.
    fields as CORE.GAMMALUT00
  0x13CC GAMMALUT0243 — Layer 0 palette/gamma correction memory region.
    fields as CORE.GAMMALUT00
  0x13D0 GAMMALUT0244 — Layer 0 palette/gamma correction memory region.
    fields as CORE.GAMMALUT00
  0x13D4 GAMMALUT0245 — Layer 0 palette/gamma correction memory region.
    fields as CORE.GAMMALUT00
  0x13D8 GAMMALUT0246 — Layer 0 palette/gamma correction memory region.
    fields as CORE.GAMMALUT00
  0x13DC GAMMALUT0247 — Layer 0 palette/gamma correction memory region.
    fields as CORE.GAMMALUT00
  0x13E0 GAMMALUT0248 — Layer 0 palette/gamma correction memory region.
    fields as CORE.GAMMALUT00
  0x13E4 GAMMALUT0249 — Layer 0 palette/gamma correction memory region.
    fields as CORE.GAMMALUT00
  0x13E8 GAMMALUT0250 — Layer 0 palette/gamma correction memory region.
    fields as CORE.GAMMALUT00
  0x13EC GAMMALUT0251 — Layer 0 palette/gamma correction memory region.
    fields as CORE.GAMMALUT00
  0x13F0 GAMMALUT0252 — Layer 0 palette/gamma correction memory region.
    fields as CORE.GAMMALUT00
  0x13F4 GAMMALUT0253 — Layer 0 palette/gamma correction memory region.
    fields as CORE.GAMMALUT00
  0x13F8 GAMMALUT0254 — Layer 0 palette/gamma correction memory region.
    fields as CORE.GAMMALUT00
  0x13FC GAMMALUT0255 — Layer 0 palette/gamma correction memory region.
    fields as CORE.GAMMALUT00
  0x1400 GAMMALUT10 — Layer 1 palette/gamma correction memory region.
    fields as CORE.GAMMALUT00
  0x1404 GAMMALUT11 — Layer 1 palette/gamma correction memory region.
    fields as CORE.GAMMALUT00
  0x1408 GAMMALUT12 — Layer 1 palette/gamma correction memory region.
    fields as CORE.GAMMALUT00
  0x140C GAMMALUT13 — Layer 1 palette/gamma correction memory region.
    fields as CORE.GAMMALUT00
  0x1410 GAMMALUT14 — Layer 1 palette/gamma correction memory region.
    fields as CORE.GAMMALUT00
  0x1414 GAMMALUT15 — Layer 1 palette/gamma correction memory region.
    fields as CORE.GAMMALUT00
  0x1418 GAMMALUT16 — Layer 1 palette/gamma correction memory region.
    fields as CORE.GAMMALUT00
  0x141C GAMMALUT17 — Layer 1 palette/gamma correction memory region.
    fields as CORE.GAMMALUT00
  0x1420 GAMMALUT18 — Layer 1 palette/gamma correction memory region.
    fields as CORE.GAMMALUT00
  0x1424 GAMMALUT19 — Layer 1 palette/gamma correction memory region.
    fields as CORE.GAMMALUT00
  0x1428 GAMMALUT110 — Layer 1 palette/gamma correction memory region.
    fields as CORE.GAMMALUT00
  0x142C GAMMALUT111 — Layer 1 palette/gamma correction memory region.
    fields as CORE.GAMMALUT00
  0x1430 GAMMALUT112 — Layer 1 palette/gamma correction memory region.
    fields as CORE.GAMMALUT00
  0x1434 GAMMALUT113 — Layer 1 palette/gamma correction memory region.
    fields as CORE.GAMMALUT00
  0x1438 GAMMALUT114 — Layer 1 palette/gamma correction memory region.
    fields as CORE.GAMMALUT00
  0x143C GAMMALUT115 — Layer 1 palette/gamma correction memory region.
    fields as CORE.GAMMALUT00
  0x1440 GAMMALUT116 — Layer 1 palette/gamma correction memory region.
    fields as CORE.GAMMALUT00
  0x1444 GAMMALUT117 — Layer 1 palette/gamma correction memory region.
    fields as CORE.GAMMALUT00
  0x1448 GAMMALUT118 — Layer 1 palette/gamma correction memory region.
    fields as CORE.GAMMALUT00
  0x144C GAMMALUT119 — Layer 1 palette/gamma correction memory region.
    fields as CORE.GAMMALUT00
  0x1450 GAMMALUT120 — Layer 1 palette/gamma correction memory region.
    fields as CORE.GAMMALUT00
  0x1454 GAMMALUT121 — Layer 1 palette/gamma correction memory region.
    fields as CORE.GAMMALUT00
  0x1458 GAMMALUT122 — Layer 1 palette/gamma correction memory region.
    fields as CORE.GAMMALUT00
  0x145C GAMMALUT123 — Layer 1 palette/gamma correction memory region.
    fields as CORE.GAMMALUT00
  0x1460 GAMMALUT124 — Layer 1 palette/gamma correction memory region.
    fields as CORE.GAMMALUT00
  0x1464 GAMMALUT125 — Layer 1 palette/gamma correction memory region.
    fields as CORE.GAMMALUT00
  0x1468 GAMMALUT126 — Layer 1 palette/gamma correction memory region.
    fields as CORE.GAMMALUT00
  0x146C GAMMALUT127 — Layer 1 palette/gamma correction memory region.
    fields as CORE.GAMMALUT00
  0x1470 GAMMALUT128 — Layer 1 palette/gamma correction memory region.
    fields as CORE.GAMMALUT00
  0x1474 GAMMALUT129 — Layer 1 palette/gamma correction memory region.
    fields as CORE.GAMMALUT00
  0x1478 GAMMALUT130 — Layer 1 palette/gamma correction memory region.
    fields as CORE.GAMMALUT00
  0x147C GAMMALUT131 — Layer 1 palette/gamma correction memory region.
    fields as CORE.GAMMALUT00
  0x1480 GAMMALUT132 — Layer 1 palette/gamma correction memory region.
    fields as CORE.GAMMALUT00
  0x1484 GAMMALUT133 — Layer 1 palette/gamma correction memory region.
    fields as CORE.GAMMALUT00
  0x1488 GAMMALUT134 — Layer 1 palette/gamma correction memory region.
    fields as CORE.GAMMALUT00
  0x148C GAMMALUT135 — Layer 1 palette/gamma correction memory region.
    fields as CORE.GAMMALUT00
  0x1490 GAMMALUT136 — Layer 1 palette/gamma correction memory region.
    fields as CORE.GAMMALUT00
  0x1494 GAMMALUT137 — Layer 1 palette/gamma correction memory region.
    fields as CORE.GAMMALUT00
  0x1498 GAMMALUT138 — Layer 1 palette/gamma correction memory region.
    fields as CORE.GAMMALUT00
  0x149C GAMMALUT139 — Layer 1 palette/gamma correction memory region.
    fields as CORE.GAMMALUT00
  0x14A0 GAMMALUT140 — Layer 1 palette/gamma correction memory region.
    fields as CORE.GAMMALUT00
  0x14A4 GAMMALUT141 — Layer 1 palette/gamma correction memory region.
    fields as CORE.GAMMALUT00
  0x14A8 GAMMALUT142 — Layer 1 palette/gamma correction memory region.
    fields as CORE.GAMMALUT00
  0x14AC GAMMALUT143 — Layer 1 palette/gamma correction memory region.
    fields as CORE.GAMMALUT00
  0x14B0 GAMMALUT144 — Layer 1 palette/gamma correction memory region.
    fields as CORE.GAMMALUT00
  0x14B4 GAMMALUT145 — Layer 1 palette/gamma correction memory region.
    fields as CORE.GAMMALUT00
  0x14B8 GAMMALUT146 — Layer 1 palette/gamma correction memory region.
    fields as CORE.GAMMALUT00
  0x14BC GAMMALUT147 — Layer 1 palette/gamma correction memory region.
    fields as CORE.GAMMALUT00
  0x14C0 GAMMALUT148 — Layer 1 palette/gamma correction memory region.
    fields as CORE.GAMMALUT00
  0x14C4 GAMMALUT149 — Layer 1 palette/gamma correction memory region.
    fields as CORE.GAMMALUT00
  0x14C8 GAMMALUT150 — Layer 1 palette/gamma correction memory region.
    fields as CORE.GAMMALUT00
  0x14CC GAMMALUT151 — Layer 1 palette/gamma correction memory region.
    fields as CORE.GAMMALUT00
  0x14D0 GAMMALUT152 — Layer 1 palette/gamma correction memory region.
    fields as CORE.GAMMALUT00
  0x14D4 GAMMALUT153 — Layer 1 palette/gamma correction memory region.
    fields as CORE.GAMMALUT00
  0x14D8 GAMMALUT154 — Layer 1 palette/gamma correction memory region.
    fields as CORE.GAMMALUT00
  0x14DC GAMMALUT155 — Layer 1 palette/gamma correction memory region.
    fields as CORE.GAMMALUT00
  0x14E0 GAMMALUT156 — Layer 1 palette/gamma correction memory region.
    fields as CORE.GAMMALUT00
  0x14E4 GAMMALUT157 — Layer 1 palette/gamma correction memory region.
    fields as CORE.GAMMALUT00
  0x14E8 GAMMALUT158 — Layer 1 palette/gamma correction memory region.
    fields as CORE.GAMMALUT00
  0x14EC GAMMALUT159 — Layer 1 palette/gamma correction memory region.
    fields as CORE.GAMMALUT00
  0x14F0 GAMMALUT160 — Layer 1 palette/gamma correction memory region.
    fields as CORE.GAMMALUT00
  0x14F4 GAMMALUT161 — Layer 1 palette/gamma correction memory region.
    fields as CORE.GAMMALUT00
  0x14F8 GAMMALUT162 — Layer 1 palette/gamma correction memory region.
    fields as CORE.GAMMALUT00
  0x14FC GAMMALUT163 — Layer 1 palette/gamma correction memory region.
    fields as CORE.GAMMALUT00
  0x1500 GAMMALUT164 — Layer 1 palette/gamma correction memory region.
    fields as CORE.GAMMALUT00
  0x1504 GAMMALUT165 — Layer 1 palette/gamma correction memory region.
    fields as CORE.GAMMALUT00
  0x1508 GAMMALUT166 — Layer 1 palette/gamma correction memory region.
    fields as CORE.GAMMALUT00
  0x150C GAMMALUT167 — Layer 1 palette/gamma correction memory region.
    fields as CORE.GAMMALUT00
  0x1510 GAMMALUT168 — Layer 1 palette/gamma correction memory region.
    fields as CORE.GAMMALUT00
  0x1514 GAMMALUT169 — Layer 1 palette/gamma correction memory region.
    fields as CORE.GAMMALUT00
  0x1518 GAMMALUT170 — Layer 1 palette/gamma correction memory region.
    fields as CORE.GAMMALUT00
  0x151C GAMMALUT171 — Layer 1 palette/gamma correction memory region.
    fields as CORE.GAMMALUT00
  0x1520 GAMMALUT172 — Layer 1 palette/gamma correction memory region.
    fields as CORE.GAMMALUT00
  0x1524 GAMMALUT173 — Layer 1 palette/gamma correction memory region.
    fields as CORE.GAMMALUT00
  0x1528 GAMMALUT174 — Layer 1 palette/gamma correction memory region.
    fields as CORE.GAMMALUT00
  0x152C GAMMALUT175 — Layer 1 palette/gamma correction memory region.
    fields as CORE.GAMMALUT00
  0x1530 GAMMALUT176 — Layer 1 palette/gamma correction memory region.
    fields as CORE.GAMMALUT00
  0x1534 GAMMALUT177 — Layer 1 palette/gamma correction memory region.
    fields as CORE.GAMMALUT00
  0x1538 GAMMALUT178 — Layer 1 palette/gamma correction memory region.
    fields as CORE.GAMMALUT00
  0x153C GAMMALUT179 — Layer 1 palette/gamma correction memory region.
    fields as CORE.GAMMALUT00
  0x1540 GAMMALUT180 — Layer 1 palette/gamma correction memory region.
    fields as CORE.GAMMALUT00
  0x1544 GAMMALUT181 — Layer 1 palette/gamma correction memory region.
    fields as CORE.GAMMALUT00
  0x1548 GAMMALUT182 — Layer 1 palette/gamma correction memory region.
    fields as CORE.GAMMALUT00
  0x154C GAMMALUT183 — Layer 1 palette/gamma correction memory region.
    fields as CORE.GAMMALUT00
  0x1550 GAMMALUT184 — Layer 1 palette/gamma correction memory region.
    fields as CORE.GAMMALUT00
  0x1554 GAMMALUT185 — Layer 1 palette/gamma correction memory region.
    fields as CORE.GAMMALUT00
  0x1558 GAMMALUT186 — Layer 1 palette/gamma correction memory region.
    fields as CORE.GAMMALUT00
  0x155C GAMMALUT187 — Layer 1 palette/gamma correction memory region.
    fields as CORE.GAMMALUT00
  0x1560 GAMMALUT188 — Layer 1 palette/gamma correction memory region.
    fields as CORE.GAMMALUT00
  0x1564 GAMMALUT189 — Layer 1 palette/gamma correction memory region.
    fields as CORE.GAMMALUT00
  0x1568 GAMMALUT190 — Layer 1 palette/gamma correction memory region.
    fields as CORE.GAMMALUT00
  0x156C GAMMALUT191 — Layer 1 palette/gamma correction memory region.
    fields as CORE.GAMMALUT00
  0x1570 GAMMALUT192 — Layer 1 palette/gamma correction memory region.
    fields as CORE.GAMMALUT00
  0x1574 GAMMALUT193 — Layer 1 palette/gamma correction memory region.
    fields as CORE.GAMMALUT00
  0x1578 GAMMALUT194 — Layer 1 palette/gamma correction memory region.
    fields as CORE.GAMMALUT00
  0x157C GAMMALUT195 — Layer 1 palette/gamma correction memory region.
    fields as CORE.GAMMALUT00
  0x1580 GAMMALUT196 — Layer 1 palette/gamma correction memory region.
    fields as CORE.GAMMALUT00
  0x1584 GAMMALUT197 — Layer 1 palette/gamma correction memory region.
    fields as CORE.GAMMALUT00
  0x1588 GAMMALUT198 — Layer 1 palette/gamma correction memory region.
    fields as CORE.GAMMALUT00
  0x158C GAMMALUT199 — Layer 1 palette/gamma correction memory region.
    fields as CORE.GAMMALUT00
  {0x460+4j} GAMMALUT{j} (j=1100..1255) — Layer 1 palette/gamma correction memory region.
    fields as CORE.GAMMALUT00
  0x1800 GAMMALUT20 — Layer 2 palette/gamma correction memory region.
    fields as CORE.GAMMALUT00
  0x1804 GAMMALUT21 — Layer 2 palette/gamma correction memory region.
    fields as CORE.GAMMALUT00
  0x1808 GAMMALUT22 — Layer 2 palette/gamma correction memory region.
    fields as CORE.GAMMALUT00
  0x180C GAMMALUT23 — Layer 2 palette/gamma correction memory region.
    fields as CORE.GAMMALUT00
  0x1810 GAMMALUT24 — Layer 2 palette/gamma correction memory region.
    fields as CORE.GAMMALUT00
  0x1814 GAMMALUT25 — Layer 2 palette/gamma correction memory region.
    fields as CORE.GAMMALUT00
  0x1818 GAMMALUT26 — Layer 2 palette/gamma correction memory region.
    fields as CORE.GAMMALUT00
  0x181C GAMMALUT27 — Layer 2 palette/gamma correction memory region.
    fields as CORE.GAMMALUT00
  0x1820 GAMMALUT28 — Layer 2 palette/gamma correction memory region.
    fields as CORE.GAMMALUT00
  0x1824 GAMMALUT29 — Layer 2 palette/gamma correction memory region.
    fields as CORE.GAMMALUT00
  0x1828 GAMMALUT210 — Layer 2 palette/gamma correction memory region.
    fields as CORE.GAMMALUT00
  0x182C GAMMALUT211 — Layer 2 palette/gamma correction memory region.
    fields as CORE.GAMMALUT00
  0x1830 GAMMALUT212 — Layer 2 palette/gamma correction memory region.
    fields as CORE.GAMMALUT00
  0x1834 GAMMALUT213 — Layer 2 palette/gamma correction memory region.
    fields as CORE.GAMMALUT00
  0x1838 GAMMALUT214 — Layer 2 palette/gamma correction memory region.
    fields as CORE.GAMMALUT00
  0x183C GAMMALUT215 — Layer 2 palette/gamma correction memory region.
    fields as CORE.GAMMALUT00
  0x1840 GAMMALUT216 — Layer 2 palette/gamma correction memory region.
    fields as CORE.GAMMALUT00
  0x1844 GAMMALUT217 — Layer 2 palette/gamma correction memory region.
    fields as CORE.GAMMALUT00
  0x1848 GAMMALUT218 — Layer 2 palette/gamma correction memory region.
    fields as CORE.GAMMALUT00
  0x184C GAMMALUT219 — Layer 2 palette/gamma correction memory region.
    fields as CORE.GAMMALUT00
  0x1850 GAMMALUT220 — Layer 2 palette/gamma correction memory region.
    fields as CORE.GAMMALUT00
  0x1854 GAMMALUT221 — Layer 2 palette/gamma correction memory region.
    fields as CORE.GAMMALUT00
  0x1858 GAMMALUT222 — Layer 2 palette/gamma correction memory region.
    fields as CORE.GAMMALUT00
  0x185C GAMMALUT223 — Layer 2 palette/gamma correction memory region.
    fields as CORE.GAMMALUT00
